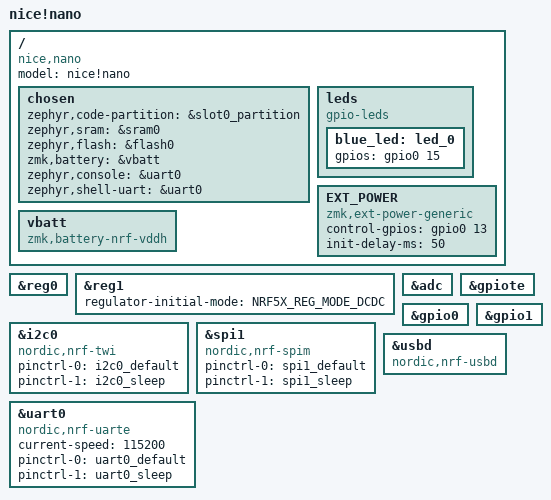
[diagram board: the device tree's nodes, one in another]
/*
 * Copyright (c) 2021 The ZMK Contributors
 *
 * SPDX-License-Identifier: MIT
 */

/dts-v1/;

#include <nordic/nrf52840_qiaa.dtsi>
#include "nice_nano_mcuboot-pinctrl.dtsi"
#include "arduino_pro_micro_pins.dtsi"

// ZMK Partitions with adafruit bootloader
/* #include "zmk_partitions.dts" */
/* #include <common/nordic/nrf52840_uf2_boot_mode.dtsi> */

// Nordic Partitions with MCUboot
#include <nordic/nrf52840_partition.dtsi>


/ {
    model = "nice!nano";
    compatible = "nice,nano";

    chosen {
        zephyr,code-partition = &slot0_partition;
        zephyr,sram = &sram0;
        zephyr,flash = &flash0;
        zmk,battery = &vbatt;

	zephyr,console = &uart0;
	zephyr,shell-uart = &uart0;
    };

    leds {
        compatible = "gpio-leds";
        blue_led: led_0 {
            gpios = <&gpio0 15 GPIO_ACTIVE_HIGH>;
        };
    };

    // Node name must match original "EXT_POWER" label to preserve user settings.
    EXT_POWER {
        compatible = "zmk,ext-power-generic";
        control-gpios = <&gpio0 13 GPIO_ACTIVE_HIGH>;
        init-delay-ms = <50>;
    };

    vbatt: vbatt {
        compatible = "zmk,battery-nrf-vddh";
    };
};

&reg0 {
    status = "okay";
};
&reg1 {
    regulator-initial-mode = <NRF5X_REG_MODE_DCDC>;
};

&adc {
    status = "okay";
};

&gpiote {
    status = "okay";
};

&gpio0 {
    status = "okay";
};

&gpio1 {
    status = "okay";
};

&i2c0 {
    compatible = "nordic,nrf-twi";
    pinctrl-0 = <&i2c0_default>;
    pinctrl-1 = <&i2c0_sleep>;
    pinctrl-names = "default", "sleep";
};

&spi1 {
    compatible = "nordic,nrf-spim";
    pinctrl-0 = <&spi1_default>;
    pinctrl-1 = <&spi1_sleep>;
    pinctrl-names = "default", "sleep";
};

&uart0 {
    compatible = "nordic,nrf-uarte";
    current-speed = <115200>;
    pinctrl-0 = <&uart0_default>;
    pinctrl-1 = <&uart0_sleep>;
    status = "okay";
    pinctrl-names = "default", "sleep";
};

zephyr_udc0: &usbd {
    compatible = "nordic,nrf-usbd";
    status = "okay";
};
